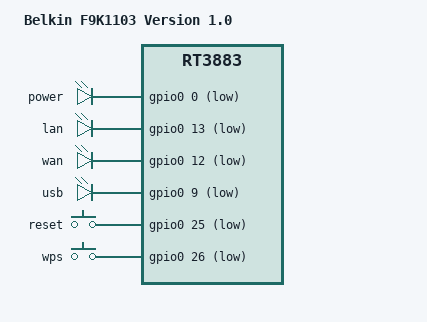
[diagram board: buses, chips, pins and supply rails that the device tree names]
// SPDX-License-Identifier: GPL-2.0-or-later OR MIT

#include "rt3883_belkin_f9k110x.dtsi"

/ {
	compatible = "belkin,f9k1103v1", "ralink,rt3883-soc";
	model = "Belkin F9K1103 Version 1.0";

	aliases {
		led-boot = &led_power;
		led-failsafe = &led_power;
		led-running = &led_power;
		led-upgrade = &led_power;
	};

	leds {
		compatible = "gpio-leds";

		/* F9K1103/BN750DB board.h: POWER=0 LAN=13 WAN=12 USB=9 */
		led_power: power {
			label = "power";
			gpios = <&gpio0 0 GPIO_ACTIVE_LOW>;
		};

		lan {
			label = "lan";
			gpios = <&gpio0 13 GPIO_ACTIVE_LOW>;
		};

		wan {
			label = "wan";
			gpios = <&gpio0 12 GPIO_ACTIVE_LOW>;
		};

		usb {
			label = "usb";
			gpios = <&gpio0 9 GPIO_ACTIVE_LOW>;
			trigger-sources = <&ohci_port1>, <&ehci_port1>,
					  <&ohci_port2>, <&ehci_port2>;
			linux,default-trigger = "usbport";
		};
	};

	keys {
		compatible = "gpio-keys-polled";
		poll-interval = <100>;

		/* F9K1103/BN750DB board.h: RESET=25 WPS=26 */
		reset {
			label = "reset";
			gpios = <&gpio0 25 GPIO_ACTIVE_LOW>;
			linux,code = <KEY_RESTART>;
		};

		wps {
			label = "wps";
			gpios = <&gpio0 26 GPIO_ACTIVE_LOW>;
			linux,code = <KEY_WPS_BUTTON>;
		};
	};
};

&ehci {
	ehci_port2: port@2 {
		reg = <2>;
		#trigger-source-cells = <0>;
	};
};

&ohci {
	ohci_port2: port@2 {
		reg = <2>;
		#trigger-source-cells = <0>;
	};
};
